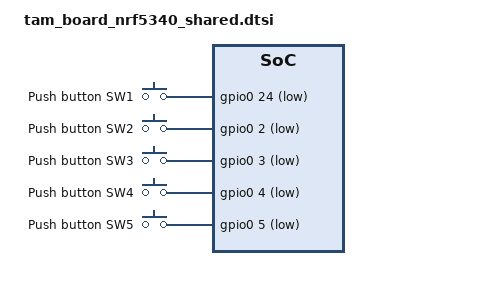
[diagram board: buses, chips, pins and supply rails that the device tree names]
#include <zephyr/dt-bindings/input/input-event-codes.h>

/ {
	buttons {
		compatible = "gpio-keys";
		button_sw1: button_sw1 {
			gpios = <&gpio0 24 GPIO_ACTIVE_LOW>;
			label = "Push button SW1";
			zephyr,code = <INPUT_KEY_0>;
		};
		button_sw2: button_sw2 {
			gpios = <&gpio0 2 (GPIO_ACTIVE_LOW | GPIO_PULL_UP)>;
			label = "Push button SW2";
			zephyr,code = <INPUT_KEY_1>;
		};
		button_sw3: button_sw3 {
			gpios = <&gpio0 3 (GPIO_ACTIVE_LOW | GPIO_PULL_UP)>;
			label = "Push button SW3";
			zephyr,code = <INPUT_KEY_2>;
		};
		button_sw4: button_sw4 {
			gpios = <&gpio0 4 (GPIO_ACTIVE_LOW | GPIO_PULL_UP)>;
			label = "Push button SW4";
			zephyr,code = <INPUT_KEY_3>;
		};
		button_sw5: button_sw5 {
			gpios = <&gpio0 5 (GPIO_ACTIVE_LOW | GPIO_PULL_UP)>;
			label = "Push button SW5";
			zephyr,code = <INPUT_KEY_4>;
		};
	};

	aliases {
		sw0 = &button_sw1;
		sw1 = &button_sw2;
		sw2 = &button_sw3;
		sw3 = &button_sw4;
		sw4 = &button_sw5;
		mcuboot-button0 = &button_sw1;
		watchdog0 = &wdt0;
	};
};
